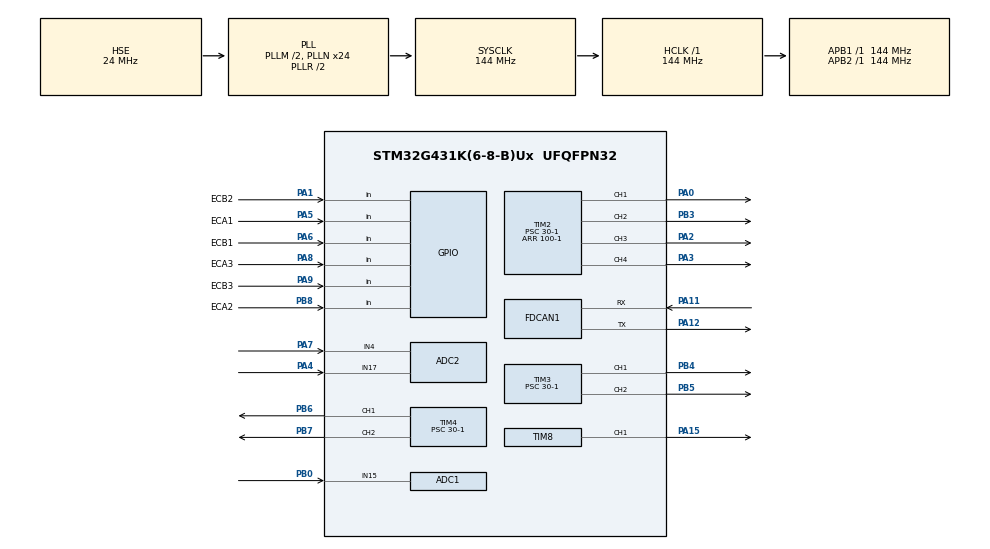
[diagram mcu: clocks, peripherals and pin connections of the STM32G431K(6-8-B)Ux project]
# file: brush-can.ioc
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ADC1.Channel-0\#ChannelRegularConversion=ADC_CHANNEL_TEMPSENSOR_ADC1
ADC1.Channel-1\#ChannelRegularConversion=ADC_CHANNEL_15
ADC1.ContinuousConvMode=ENABLE
ADC1.DMAContinuousRequests=ENABLE
ADC1.NbrOfConversion=2
ADC1.NbrOfConversionFlag=1
ADC1.OffsetNumber-0\#ChannelRegularConversion=ADC_OFFSET_NONE
ADC1.OffsetNumber-1\#ChannelRegularConversion=ADC_OFFSET_NONE
ADC1.Overrun=ADC_OVR_DATA_OVERWRITTEN
ADC1.Rank-0\#ChannelRegularConversion=1
ADC1.Rank-1\#ChannelRegularConversion=2
ADC1.SamplingTime-0\#ChannelRegularConversion=ADC_SAMPLETIME_92CYCLES_5
ADC1.SamplingTime-1\#ChannelRegularConversion=ADC_SAMPLETIME_92CYCLES_5
ADC1.master=1
ADC2.Channel-0\#ChannelRegularConversion=ADC_CHANNEL_4
ADC2.Channel-1\#ChannelRegularConversion=ADC_CHANNEL_17
ADC2.ContinuousConvMode=ENABLE
ADC2.DMAContinuousRequests=ENABLE
ADC2.NbrOfConversion=2
ADC2.NbrOfConversionFlag=1
ADC2.OffsetNumber-0\#ChannelRegularConversion=ADC_OFFSET_NONE
ADC2.OffsetNumber-1\#ChannelRegularConversion=ADC_OFFSET_NONE
ADC2.Overrun=ADC_OVR_DATA_OVERWRITTEN
ADC2.Rank-0\#ChannelRegularConversion=1
ADC2.Rank-1\#ChannelRegularConversion=2
ADC2.SamplingTime-0\#ChannelRegularConversion=ADC_SAMPLETIME_92CYCLES_5
ADC2.SamplingTime-1\#ChannelRegularConversion=ADC_SAMPLETIME_92CYCLES_5
Dma.ADC1.0.Direction=DMA_PERIPH_TO_MEMORY
Dma.ADC1.0.EventEnable=DISABLE
Dma.ADC1.0.Instance=DMA1_Channel1
Dma.ADC1.0.MemDataAlignment=DMA_MDATAALIGN_HALFWORD
Dma.ADC1.0.MemInc=DMA_MINC_ENABLE
Dma.ADC1.0.Mode=DMA_NORMAL
Dma.ADC1.0.PeriphDataAlignment=DMA_PDATAALIGN_HALFWORD
Dma.ADC1.0.PeriphInc=DMA_PINC_DISABLE
Dma.ADC1.0.Polarity=HAL_DMAMUX_REQ_GEN_RISING
Dma.ADC1.0.Priority=DMA_PRIORITY_MEDIUM
Dma.ADC1.0.RequestNumber=1
Dma.ADC1.0.SignalID=NONE
Dma.ADC1.0.SyncEnable=DISABLE
Dma.ADC1.0.SyncPolarity=HAL_DMAMUX_SYNC_NO_EVENT
Dma.ADC1.0.SyncRequestNumber=1
Dma.ADC1.0.SyncSignalID=NONE
Dma.ADC2.1.Direction=DMA_PERIPH_TO_MEMORY
Dma.ADC2.1.EventEnable=DISABLE
Dma.ADC2.1.Instance=DMA1_Channel2
Dma.ADC2.1.MemDataAlignment=DMA_MDATAALIGN_HALFWORD
Dma.ADC2.1.MemInc=DMA_MINC_ENABLE
Dma.ADC2.1.Mode=DMA_NORMAL
Dma.ADC2.1.PeriphDataAlignment=DMA_PDATAALIGN_HALFWORD
Dma.ADC2.1.PeriphInc=DMA_PINC_DISABLE
Dma.ADC2.1.Polarity=HAL_DMAMUX_REQ_GEN_RISING
Dma.ADC2.1.Priority=DMA_PRIORITY_MEDIUM
Dma.ADC2.1.RequestNumber=1
Dma.ADC2.1.SignalID=NONE
Dma.ADC2.1.SyncEnable=DISABLE
Dma.ADC2.1.SyncPolarity=HAL_DMAMUX_SYNC_NO_EVENT
Dma.ADC2.1.SyncRequestNumber=1
Dma.ADC2.1.SyncSignalID=NONE
Dma.Request0=ADC1
Dma.Request1=ADC2
FDCAN1.CalculateBaudRateNominal=1800000
FDCAN1.CalculateTimeBitNominal=555
FDCAN1.CalculateTimeQuantumNominal=111.11111111111111
FDCAN1.FrameFormat=FDCAN_FRAME_FD_NO_BRS
Mcu.Family=STM32G4
Mcu.Name=STM32G431K(6-8-B)Ux
Mcu.Package=UFQFPN32
NVIC.DMA1_Channel1_IRQn=true\:0\:0\:false\:false\:true\:false\:true\:true
NVIC.DMA1_Channel2_IRQn=true\:0\:0\:false\:false\:true\:false\:true\:true
NVIC.PriorityGroup=NVIC_PRIORITYGROUP_4
NVIC.TIM1_TRG_COM_TIM17_IRQn=true\:0\:0\:false\:false\:true\:true\:true\:true
PA0.Signal=S_TIM2_CH1
PA1.GPIO_Label=ECB2
PA1.Signal=GPIO_Input
PA11.Mode=FDCAN_Activate
PA11.Signal=FDCAN1_RX
PA12.Mode=FDCAN_Activate
PA12.Signal=FDCAN1_TX
PA13.Mode=Serial_Wire
PA13.Signal=SYS_JTMS-SWDIO
PA14.Mode=Serial_Wire
PA14.Signal=SYS_JTCK-SWCLK
PA15.Signal=S_TIM8_CH1
PA2.Signal=S_TIM2_CH3
PA3.Signal=S_TIM2_CH4
PA4.Mode=IN17-Single-Ended
PA4.Signal=ADC2_IN17
PA5.GPIO_Label=ECA1
PA5.Signal=GPIO_Input
PA6.GPIO_Label=ECB1
PA6.Signal=GPIO_Input
PA7.Mode=IN4-Single-Ended
PA7.Signal=ADC2_IN4
PA8.GPIO_Label=ECA3
PA8.Signal=GPIO_Input
PA9.GPIO_Label=ECB3
PA9.Signal=GPIO_Input
PB0.Mode=IN15-Single-Ended
PB0.Signal=ADC1_IN15
PB3.Signal=S_TIM2_CH2
PB4.Signal=S_TIM3_CH1
PB5.Signal=S_TIM3_CH2
PB6.Signal=S_TIM4_CH1
PB7.Signal=S_TIM4_CH2
PB8-BOOT0.GPIO_Label=ECA2
PB8-BOOT0.Signal=GPIO_Input
PF0-OSC_IN.Mode=HSE-External-Oscillator
PF0-OSC_IN.Signal=RCC_OSC_IN
PF1-OSC_OUT.Mode=HSE-External-Oscillator
PF1-OSC_OUT.Signal=RCC_OSC_OUT
ProjectManager.HeapSize=0x200
ProjectManager.StackSize=0x400
ProjectManager.TargetToolchain=STM32CubeIDE
RCC.ADC12Freq_Value=144000000
RCC.AHBFreq_Value=144000000
RCC.APB1Freq_Value=144000000
RCC.APB1TimFreq_Value=144000000
RCC.APB2Freq_Value=144000000
RCC.APB2TimFreq_Value=144000000
RCC.CortexFreq_Value=144000000
RCC.EXTERNAL_CLOCK_VALUE=12288000
RCC.FDCANCLockSelection=RCC_FDCANCLKSOURCE_PLL
RCC.HCLKFreq_Value=144000000
RCC.HSE_VALUE=24000000
RCC.HSI48_VALUE=48000000
RCC.HSI_VALUE=16000000
RCC.LSE_VALUE=32768
RCC.PLLM=RCC_PLLM_DIV2
RCC.PLLN=24
RCC.PLLSourceVirtual=RCC_PLLSOURCE_HSE
RCC.SYSCLKFreq_VALUE=144000000
RCC.SYSCLKSource=RCC_SYSCLKSOURCE_PLLCLK
RCC.USBFreq_Value=144000000
RCC.VCOOutputFreq_Value=288000000
SH.S_TIM2_CH1.0=TIM2_CH1,PWM Generation1 CH1
SH.S_TIM2_CH2.0=TIM2_CH2,PWM Generation2 CH2
SH.S_TIM2_CH3.0=TIM2_CH3,PWM Generation3 CH3
SH.S_TIM2_CH4.0=TIM2_CH4,PWM Generation4 CH4
SH.S_TIM3_CH1.0=TIM3_CH1,PWM Generation1 CH1
SH.S_TIM3_CH2.0=TIM3_CH2,PWM Generation2 CH2
SH.S_TIM4_CH1.0=TIM4_CH1,PWM Generation1 CH1
SH.S_TIM4_CH2.0=TIM4_CH2,PWM Generation2 CH2
SH.S_TIM8_CH1.0=TIM8_CH1,PWM Generation1 CH1
TIM16.Prescaler=144-1
TIM17.PeriodNoDither=50-1
TIM17.Prescaler=144-1
TIM2.Channel-PWM\ Generation1\ CH1=TIM_CHANNEL_1
TIM2.Channel-PWM\ Generation2\ CH2=TIM_CHANNEL_2
TIM2.Channel-PWM\ Generation3\ CH3=TIM_CHANNEL_3
TIM2.Channel-PWM\ Generation4\ CH4=TIM_CHANNEL_4
TIM2.PeriodNoDither=100-1
TIM2.Prescaler=30-1
TIM3.Channel-PWM\ Generation1\ CH1=TIM_CHANNEL_1
TIM3.Channel-PWM\ Generation2\ CH2=TIM_CHANNEL_2
TIM3.PeriodNoDither=100-1
TIM3.Prescaler=30-1
TIM4.Channel-PWM\ Generation1\ CH1=TIM_CHANNEL_1
TIM4.Channel-PWM\ Generation2\ CH2=TIM_CHANNEL_2
TIM4.PeriodNoDither=100-1
TIM4.Prescaler=30-1
TIM8.Channel-PWM\ Generation1\ CH1=TIM_CHANNEL_1
TIM8.PeriodNoDither=100-1
TIM8.Prescaler=30-1
VP_ADC1_TempSens_Input.Mode=IN-TempSens
VP_SYS_VS_DBSignals.Mode=DisableDeadBatterySignals
VP_TIM16_VS_ClockSourceINT.Mode=Enable_Timer
VP_TIM17_VS_ClockSourceINT.Mode=Enable_Timer
VP_TIM2_VS_ClockSourceINT.Mode=Internal
VP_TIM3_VS_ClockSourceINT.Mode=Internal
VP_TIM4_VS_ClockSourceINT.Mode=Internal
VP_TIM8_VS_ClockSourceINT.Mode=Internal
board=custom

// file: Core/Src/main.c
/* USER CODE BEGIN Header */
/**
  ******************************************************************************
  * @file           : main.c
  * @brief          : Main program body
  ******************************************************************************
  * @attention
  *
  * Copyright (c) 2024 STMicroelectronics.
  * All rights reserved.
  *
  * This software is licensed under terms that can be found in the LICENSE file
  * in the root directory of this software component.
  * If no LICENSE file comes with this software, it is provided AS-IS.
  *
  ******************************************************************************
  */
/* USER CODE END Header */
#include "main.h"

/* USER CODE BEGIN Includes */
#include "app.h"
/* USER CODE END Includes */

ADC_HandleTypeDef hadc1;
ADC_HandleTypeDef hadc2;
DMA_HandleTypeDef hdma_adc1;
DMA_HandleTypeDef hdma_adc2;

FDCAN_HandleTypeDef hfdcan1;

TIM_HandleTypeDef htim2;
TIM_HandleTypeDef htim3;
TIM_HandleTypeDef htim4;
TIM_HandleTypeDef htim8;
TIM_HandleTypeDef htim16;
TIM_HandleTypeDef htim17;

void SystemClock_Config(void);
static void MX_GPIO_Init(void);
static void MX_DMA_Init(void);
static void MX_FDCAN1_Init(void);
static void MX_ADC1_Init(void);
static void MX_ADC2_Init(void);
static void MX_TIM2_Init(void);
static void MX_TIM3_Init(void);
static void MX_TIM4_Init(void);
static void MX_TIM8_Init(void);
static void MX_TIM16_Init(void);
static void MX_TIM17_Init(void);

int main(void)
{

  /* MCU Configuration--------------------------------------------------------*/

  /* Reset of all peripherals, Initializes the Flash interface and the Systick. */
  HAL_Init();

  /* Configure the system clock */
  SystemClock_Config();

  /* Initialize all configured peripherals */
  MX_GPIO_Init();
  MX_DMA_Init();
  MX_FDCAN1_Init();
  MX_ADC1_Init();
  MX_ADC2_Init();
  MX_TIM2_Init();
  MX_TIM3_Init();
  MX_TIM4_Init();
  MX_TIM8_Init();
  MX_TIM16_Init();
  MX_TIM17_Init();

  /* Infinite loop */
  /* USER CODE BEGIN WHILE */
  App_Init();
  while (1)
  {
	  App_Loop();
    /* USER CODE END WHILE */

  }
}

void SystemClock_Config(void)
{
  RCC_OscInitTypeDef RCC_OscInitStruct = {0};
  RCC_ClkInitTypeDef RCC_ClkInitStruct = {0};

  /** Configure the main internal regulator output voltage
  */
  HAL_PWREx_ControlVoltageScaling(PWR_REGULATOR_VOLTAGE_SCALE1);

  /** Initializes the RCC Oscillators according to the specified parameters
  * in the RCC_OscInitTypeDef structure.
  */
  RCC_OscInitStruct.OscillatorType = RCC_OSCILLATORTYPE_HSE;
  RCC_OscInitStruct.HSEState = RCC_HSE_ON;
  RCC_OscInitStruct.PLL.PLLState = RCC_PLL_ON;
  RCC_OscInitStruct.PLL.PLLSource = RCC_PLLSOURCE_HSE;
  RCC_OscInitStruct.PLL.PLLM = RCC_PLLM_DIV2;
  RCC_OscInitStruct.PLL.PLLN = 24;
  RCC_OscInitStruct.PLL.PLLP = RCC_PLLP_DIV2;
  RCC_OscInitStruct.PLL.PLLQ = RCC_PLLQ_DIV2;
  RCC_OscInitStruct.PLL.PLLR = RCC_PLLR_DIV2;
  if (HAL_RCC_OscConfig(&RCC_OscInitStruct) != HAL_OK)
  {
    Error_Handler();
  }

  /** Initializes the CPU, AHB and APB buses clocks
  */
  RCC_ClkInitStruct.ClockType = RCC_CLOCKTYPE_HCLK|RCC_CLOCKTYPE_SYSCLK
                              |RCC_CLOCKTYPE_PCLK1|RCC_CLOCKTYPE_PCLK2;
  RCC_ClkInitStruct.SYSCLKSource = RCC_SYSCLKSOURCE_PLLCLK;
  RCC_ClkInitStruct.AHBCLKDivider = RCC_SYSCLK_DIV1;
  RCC_ClkInitStruct.APB1CLKDivider = RCC_HCLK_DIV1;
  RCC_ClkInitStruct.APB2CLKDivider = RCC_HCLK_DIV1;

  if (HAL_RCC_ClockConfig(&RCC_ClkInitStruct, FLASH_LATENCY_4) != HAL_OK)
  {
    Error_Handler();
  }
}

static void MX_ADC1_Init(void)
{

  ADC_MultiModeTypeDef multimode = {0};
  ADC_ChannelConfTypeDef sConfig = {0};

  /** Common config
  */
  hadc1.Instance = ADC1;
  hadc1.Init.ClockPrescaler = ADC_CLOCK_SYNC_PCLK_DIV4;
  hadc1.Init.Resolution = ADC_RESOLUTION_12B;
  hadc1.Init.DataAlign = ADC_DATAALIGN_RIGHT;
  hadc1.Init.GainCompensation = 0;
  hadc1.Init.ScanConvMode = ADC_SCAN_ENABLE;
  hadc1.Init.EOCSelection = ADC_EOC_SINGLE_CONV;
  hadc1.Init.LowPowerAutoWait = DISABLE;
  hadc1.Init.ContinuousConvMode = ENABLE;
  hadc1.Init.NbrOfConversion = 2;
  hadc1.Init.DiscontinuousConvMode = DISABLE;
  hadc1.Init.ExternalTrigConv = ADC_SOFTWARE_START;
  hadc1.Init.ExternalTrigConvEdge = ADC_EXTERNALTRIGCONVEDGE_NONE;
  hadc1.Init.DMAContinuousRequests = ENABLE;
  hadc1.Init.Overrun = ADC_OVR_DATA_OVERWRITTEN;
  hadc1.Init.OversamplingMode = DISABLE;
  if (HAL_ADC_Init(&hadc1) != HAL_OK)
  {
    Error_Handler();
  }

  /** Configure the ADC multi-mode
  */
  multimode.Mode = ADC_MODE_INDEPENDENT;
  if (HAL_ADCEx_MultiModeConfigChannel(&hadc1, &multimode) != HAL_OK)
  {
    Error_Handler();
  }

  /** Configure Regular Channel
  */
  sConfig.Channel = ADC_CHANNEL_TEMPSENSOR_ADC1;
  sConfig.Rank = ADC_REGULAR_RANK_1;
  sConfig.SamplingTime = ADC_SAMPLETIME_92CYCLES_5;
  sConfig.SingleDiff = ADC_SINGLE_ENDED;
  sConfig.OffsetNumber = ADC_OFFSET_NONE;
  sConfig.Offset = 0;
  if (HAL_ADC_ConfigChannel(&hadc1, &sConfig) != HAL_OK)
  {
    Error_Handler();
  }

  /** Configure Regular Channel
  */
  sConfig.Channel = ADC_CHANNEL_15;
  sConfig.Rank = ADC_REGULAR_RANK_2;
  if (HAL_ADC_ConfigChannel(&hadc1, &sConfig) != HAL_OK)
  {
    Error_Handler();
  }

}

static void MX_ADC2_Init(void)
{

  ADC_ChannelConfTypeDef sConfig = {0};

  /** Common config
  */
  hadc2.Instance = ADC2;
  hadc2.Init.ClockPrescaler = ADC_CLOCK_SYNC_PCLK_DIV4;
  hadc2.Init.Resolution = ADC_RESOLUTION_12B;
  hadc2.Init.DataAlign = ADC_DATAALIGN_RIGHT;
  hadc2.Init.GainCompensation = 0;
  hadc2.Init.ScanConvMode = ADC_SCAN_ENABLE;
  hadc2.Init.EOCSelection = ADC_EOC_SINGLE_CONV;
  hadc2.Init.LowPowerAutoWait = DISABLE;
  hadc2.Init.ContinuousConvMode = ENABLE;
  hadc2.Init.NbrOfConversion = 2;
  hadc2.Init.DiscontinuousConvMode = DISABLE;
  hadc2.Init.ExternalTrigConv = ADC_SOFTWARE_START;
  hadc2.Init.ExternalTrigConvEdge = ADC_EXTERNALTRIGCONVEDGE_NONE;
  hadc2.Init.DMAContinuousRequests = ENABLE;
  hadc2.Init.Overrun = ADC_OVR_DATA_OVERWRITTEN;
  hadc2.Init.OversamplingMode = DISABLE;
  if (HAL_ADC_Init(&hadc2) != HAL_OK)
  {
    Error_Handler();
  }

  /** Configure Regular Channel
  */
  sConfig.Channel = ADC_CHANNEL_4;
  sConfig.Rank = ADC_REGULAR_RANK_1;
  sConfig.SamplingTime = ADC_SAMPLETIME_92CYCLES_5;
  sConfig.SingleDiff = ADC_SINGLE_ENDED;
  sConfig.OffsetNumber = ADC_OFFSET_NONE;
  sConfig.Offset = 0;
  if (HAL_ADC_ConfigChannel(&hadc2, &sConfig) != HAL_OK)
  {
    Error_Handler();
  }

  /** Configure Regular Channel
  */
  sConfig.Channel = ADC_CHANNEL_17;
  sConfig.Rank = ADC_REGULAR_RANK_2;
  if (HAL_ADC_ConfigChannel(&hadc2, &sConfig) != HAL_OK)
  {
    Error_Handler();
  }

}

static void MX_FDCAN1_Init(void)
{

  hfdcan1.Instance = FDCAN1;
  hfdcan1.Init.ClockDivider = FDCAN_CLOCK_DIV1;
  hfdcan1.Init.FrameFormat = FDCAN_FRAME_FD_NO_BRS;
  hfdcan1.Init.Mode = FDCAN_MODE_NORMAL;
  hfdcan1.Init.AutoRetransmission = DISABLE;
  hfdcan1.Init.TransmitPause = DISABLE;
  hfdcan1.Init.ProtocolException = DISABLE;
  hfdcan1.Init.NominalPrescaler = 16;
  hfdcan1.Init.NominalSyncJumpWidth = 1;
  hfdcan1.Init.NominalTimeSeg1 = 2;
  hfdcan1.Init.NominalTimeSeg2 = 2;
  hfdcan1.Init.DataPrescaler = 1;
  hfdcan1.Init.DataSyncJumpWidth = 1;
  hfdcan1.Init.DataTimeSeg1 = 1;
  hfdcan1.Init.DataTimeSeg2 = 1;
  hfdcan1.Init.StdFiltersNbr = 0;
  hfdcan1.Init.ExtFiltersNbr = 0;
  hfdcan1.Init.TxFifoQueueMode = FDCAN_TX_FIFO_OPERATION;
  if (HAL_FDCAN_Init(&hfdcan1) != HAL_OK)
  {
    Error_Handler();
  }

}

static void MX_TIM2_Init(void)
{

  TIM_ClockConfigTypeDef sClockSourceConfig = {0};
  TIM_MasterConfigTypeDef sMasterConfig = {0};
  TIM_OC_InitTypeDef sConfigOC = {0};

  htim2.Instance = TIM2;
  htim2.Init.Prescaler = 30-1;
  htim2.Init.CounterMode = TIM_COUNTERMODE_UP;
  htim2.Init.Period = 99;
  htim2.Init.ClockDivision = TIM_CLOCKDIVISION_DIV1;
  htim2.Init.AutoReloadPreload = TIM_AUTORELOAD_PRELOAD_DISABLE;
  if (HAL_TIM_Base_Init(&htim2) != HAL_OK)
  {
    Error_Handler();
  }
  sClockSourceConfig.ClockSource = TIM_CLOCKSOURCE_INTERNAL;
  if (HAL_TIM_ConfigClockSource(&htim2, &sClockSourceConfig) != HAL_OK)
  {
    Error_Handler();
  }
  if (HAL_TIM_PWM_Init(&htim2) != HAL_OK)
  {
    Error_Handler();
  }
  sMasterConfig.MasterOutputTrigger = TIM_TRGO_RESET;
  sMasterConfig.MasterSlaveMode = TIM_MASTERSLAVEMODE_DISABLE;
  if (HAL_TIMEx_MasterConfigSynchronization(&htim2, &sMasterConfig) != HAL_OK)
  {
    Error_Handler();
  }
  sConfigOC.OCMode = TIM_OCMODE_PWM1;
  sConfigOC.Pulse = 0;
  sConfigOC.OCPolarity = TIM_OCPOLARITY_HIGH;
  sConfigOC.OCFastMode = TIM_OCFAST_DISABLE;
  if (HAL_TIM_PWM_ConfigChannel(&htim2, &sConfigOC, TIM_CHANNEL_1) != HAL_OK)
  {
    Error_Handler();
  }
  if (HAL_TIM_PWM_ConfigChannel(&htim2, &sConfigOC, TIM_CHANNEL_2) != HAL_OK)
  {
    Error_Handler();
  }
  if (HAL_TIM_PWM_ConfigChannel(&htim2, &sConfigOC, TIM_CHANNEL_3) != HAL_OK)
  {
    Error_Handler();
  }
  if (HAL_TIM_PWM_ConfigChannel(&htim2, &sConfigOC, TIM_CHANNEL_4) != HAL_OK)
  {
    Error_Handler();
  }
  HAL_TIM_MspPostInit(&htim2);

}

static void MX_TIM3_Init(void)
{

  TIM_ClockConfigTypeDef sClockSourceConfig = {0};
  TIM_MasterConfigTypeDef sMasterConfig = {0};
  TIM_OC_InitTypeDef sConfigOC = {0};

  htim3.Instance = TIM3;
  htim3.Init.Prescaler = 30-1;
  htim3.Init.CounterMode = TIM_COUNTERMODE_UP;
  htim3.Init.Period = 99;
  htim3.Init.ClockDivision = TIM_CLOCKDIVISION_DIV1;
  htim3.Init.AutoReloadPreload = TIM_AUTORELOAD_PRELOAD_DISABLE;
  if (HAL_TIM_Base_Init(&htim3) != HAL_OK)
  {
    Error_Handler();
  }
  sClockSourceConfig.ClockSource = TIM_CLOCKSOURCE_INTERNAL;
  if (HAL_TIM_ConfigClockSource(&htim3, &sClockSourceConfig) != HAL_OK)
  {
    Error_Handler();
  }
  if (HAL_TIM_PWM_Init(&htim3) != HAL_OK)
  {
    Error_Handler();
  }
  sMasterConfig.MasterOutputTrigger = TIM_TRGO_RESET;
  sMasterConfig.MasterSlaveMode = TIM_MASTERSLAVEMODE_DISABLE;
  if (HAL_TIMEx_MasterConfigSynchronization(&htim3, &sMasterConfig) != HAL_OK)
  {
    Error_Handler();
  }
  sConfigOC.OCMode = TIM_OCMODE_PWM1;
  sConfigOC.Pulse = 0;
  sConfigOC.OCPolarity = TIM_OCPOLARITY_HIGH;
  sConfigOC.OCFastMode = TIM_OCFAST_DISABLE;
  if (HAL_TIM_PWM_ConfigChannel(&htim3, &sConfigOC, TIM_CHANNEL_1) != HAL_OK)
  {
    Error_Handler();
  }
  if (HAL_TIM_PWM_ConfigChannel(&htim3, &sConfigOC, TIM_CHANNEL_2) != HAL_OK)
  {
    Error_Handler();
  }
  HAL_TIM_MspPostInit(&htim3);

}

static void MX_TIM4_Init(void)
{

  TIM_ClockConfigTypeDef sClockSourceConfig = {0};
  TIM_MasterConfigTypeDef sMasterConfig = {0};
  TIM_OC_InitTypeDef sConfigOC = {0};

  htim4.Instance = TIM4;
  htim4.Init.Prescaler = 30-1;
  htim4.Init.CounterMode = TIM_COUNTERMODE_UP;
  htim4.Init.Period = 99;
  htim4.Init.ClockDivision = TIM_CLOCKDIVISION_DIV1;
  htim4.Init.AutoReloadPreload = TIM_AUTORELOAD_PRELOAD_DISABLE;
  if (HAL_TIM_Base_Init(&htim4) != HAL_OK)
  {
    Error_Handler();
  }
  sClockSourceConfig.ClockSource = TIM_CLOCKSOURCE_INTERNAL;
  if (HAL_TIM_ConfigClockSource(&htim4, &sClockSourceConfig) != HAL_OK)
  {
    Error_Handler();
  }
  if (HAL_TIM_PWM_Init(&htim4) != HAL_OK)
  {
    Error_Handler();
  }
  sMasterConfig.MasterOutputTrigger = TIM_TRGO_RESET;
  sMasterConfig.MasterSlaveMode = TIM_MASTERSLAVEMODE_DISABLE;
  if (HAL_TIMEx_MasterConfigSynchronization(&htim4, &sMasterConfig) != HAL_OK)
  {
    Error_Handler();
  }
  sConfigOC.OCMode = TIM_OCMODE_PWM1;
  sConfigOC.Pulse = 0;
  sConfigOC.OCPolarity = TIM_OCPOLARITY_HIGH;
  sConfigOC.OCFastMode = TIM_OCFAST_DISABLE;
  if (HAL_TIM_PWM_ConfigChannel(&htim4, &sConfigOC, TIM_CHANNEL_1) != HAL_OK)
  {
    Error_Handler();
  }
  if (HAL_TIM_PWM_ConfigChannel(&htim4, &sConfigOC, TIM_CHANNEL_2) != HAL_OK)
  {
    Error_Handler();
  }
  HAL_TIM_MspPostInit(&htim4);

}

static void MX_TIM8_Init(void)
{

  TIM_ClockConfigTypeDef sClockSourceConfig = {0};
  TIM_MasterConfigTypeDef sMasterConfig = {0};
  TIM_OC_InitTypeDef sConfigOC = {0};
  TIM_BreakDeadTimeConfigTypeDef sBreakDeadTimeConfig = {0};

  htim8.Instance = TIM8;
  htim8.Init.Prescaler = 30-1;
  htim8.Init.CounterMode = TIM_COUNTERMODE_UP;
  htim8.Init.Period = 99;
  htim8.Init.ClockDivision = TIM_CLOCKDIVISION_DIV1;
  htim8.Init.RepetitionCounter = 0;
  htim8.Init.AutoReloadPreload = TIM_AUTORELOAD_PRELOAD_DISABLE;
  if (HAL_TIM_Base_Init(&htim8) != HAL_OK)
  {
    Error_Handler();
  }
  sClockSourceConfig.ClockSource = TIM_CLOCKSOURCE_INTERNAL;
  if (HAL_TIM_ConfigClockSource(&htim8, &sClockSourceConfig) != HAL_OK)
  {
    Error_Handler();
  }
  if (HAL_TIM_PWM_Init(&htim8) != HAL_OK)
  {
    Error_Handler();
  }
  sMasterConfig.MasterOutputTrigger = TIM_TRGO_RESET;
  sMasterConfig.MasterOutputTrigger2 = TIM_TRGO2_RESET;
  sMasterConfig.MasterSlaveMode = TIM_MASTERSLAVEMODE_DISABLE;
  if (HAL_TIMEx_MasterConfigSynchronization(&htim8, &sMasterConfig) != HAL_OK)
  {
    Error_Handler();
  }
  sConfigOC.OCMode = TIM_OCMODE_PWM1;
  sConfigOC.Pulse = 0;
  sConfigOC.OCPolarity = TIM_OCPOLARITY_HIGH;
  sConfigOC.OCNPolarity = TIM_OCNPOLARITY_HIGH;
  sConfigOC.OCFastMode = TIM_OCFAST_DISABLE;
  sConfigOC.OCIdleState = TIM_OCIDLESTATE_RESET;
  sConfigOC.OCNIdleState = TIM_OCNIDLESTATE_RESET;
  if (HAL_TIM_PWM_ConfigChannel(&htim8, &sConfigOC, TIM_CHANNEL_1) != HAL_OK)
  {
    Error_Handler();
  }
  sBreakDeadTimeConfig.OffStateRunMode = TIM_OSSR_DISABLE;
  sBreakDeadTimeConfig.OffStateIDLEMode = TIM_OSSI_DISABLE;
  sBreakDeadTimeConfig.LockLevel = TIM_LOCKLEVEL_OFF;
  sBreakDeadTimeConfig.DeadTime = 0;
  sBreakDeadTimeConfig.BreakState = TIM_BREAK_DISABLE;
  sBreakDeadTimeConfig.BreakPolarity = TIM_BREAKPOLARITY_HIGH;
  sBreakDeadTimeConfig.BreakFilter = 0;
  sBreakDeadTimeConfig.BreakAFMode = TIM_BREAK_AFMODE_INPUT;
  sBreakDeadTimeConfig.Break2State = TIM_BREAK2_DISABLE;
  sBreakDeadTimeConfig.Break2Polarity = TIM_BREAK2POLARITY_HIGH;
  sBreakDeadTimeConfig.Break2Filter = 0;
  sBreakDeadTimeConfig.Break2AFMode = TIM_BREAK_AFMODE_INPUT;
  sBreakDeadTimeConfig.AutomaticOutput = TIM_AUTOMATICOUTPUT_DISABLE;
  if (HAL_TIMEx_ConfigBreakDeadTime(&htim8, &sBreakDeadTimeConfig) != HAL_OK)
  {
    Error_Handler();
  }
  HAL_TIM_MspPostInit(&htim8);

}

static void MX_TIM16_Init(void)
{

  htim16.Instance = TIM16;
  htim16.Init.Prescaler = 144-1;
  htim16.Init.CounterMode = TIM_COUNTERMODE_UP;
  htim16.Init.Period = 65535;
  htim16.Init.ClockDivision = TIM_CLOCKDIVISION_DIV1;
  htim16.Init.RepetitionCounter = 0;
  htim16.Init.AutoReloadPreload = TIM_AUTORELOAD_PRELOAD_DISABLE;
  if (HAL_TIM_Base_Init(&htim16) != HAL_OK)
  {
    Error_Handler();
  }

}

static void MX_TIM17_Init(void)
{

  htim17.Instance = TIM17;
  htim17.Init.Prescaler = 144-1;
  htim17.Init.CounterMode = TIM_COUNTERMODE_UP;
  htim17.Init.Period = 49;
  htim17.Init.ClockDivision = TIM_CLOCKDIVISION_DIV1;
  htim17.Init.RepetitionCounter = 0;
  htim17.Init.AutoReloadPreload = TIM_AUTORELOAD_PRELOAD_DISABLE;
  if (HAL_TIM_Base_Init(&htim17) != HAL_OK)
  {
    Error_Handler();
  }

}

static void MX_DMA_Init(void)
{

  /* DMA controller clock enable */
  __HAL_RCC_DMAMUX1_CLK_ENABLE();
  __HAL_RCC_DMA1_CLK_ENABLE();

  /* DMA interrupt init */
  /* DMA1_Channel1_IRQn interrupt configuration */
  HAL_NVIC_SetPriority(DMA1_Channel1_IRQn, 0, 0);
  HAL_NVIC_EnableIRQ(DMA1_Channel1_IRQn);
  /* DMA1_Channel2_IRQn interrupt configuration */
  HAL_NVIC_SetPriority(DMA1_Channel2_IRQn, 0, 0);
  HAL_NVIC_EnableIRQ(DMA1_Channel2_IRQn);

}

static void MX_GPIO_Init(void)
{
  GPIO_InitTypeDef GPIO_InitStruct = {0};

  /* GPIO Ports Clock Enable */
  __HAL_RCC_GPIOF_CLK_ENABLE();
  __HAL_RCC_GPIOA_CLK_ENABLE();
  __HAL_RCC_GPIOB_CLK_ENABLE();

  /*Configure GPIO pins : ECB2_Pin ECA1_Pin ECB1_Pin ECA3_Pin
                           ECB3_Pin */
  GPIO_InitStruct.Pin = ECB2_Pin|ECA1_Pin|ECB1_Pin|ECA3_Pin
                          |ECB3_Pin;
  GPIO_InitStruct.Mode = GPIO_MODE_INPUT;
  GPIO_InitStruct.Pull = GPIO_NOPULL;
  HAL_GPIO_Init(GPIOA, &GPIO_InitStruct);

  /*Configure GPIO pin : ECA2_Pin */
  GPIO_InitStruct.Pin = ECA2_Pin;
  GPIO_InitStruct.Mode = GPIO_MODE_INPUT;
  GPIO_InitStruct.Pull = GPIO_NOPULL;
  HAL_GPIO_Init(ECA2_GPIO_Port, &GPIO_InitStruct);

}

void Error_Handler(void)
{
  __disable_irq();
  while (1)
  {
  }
}
